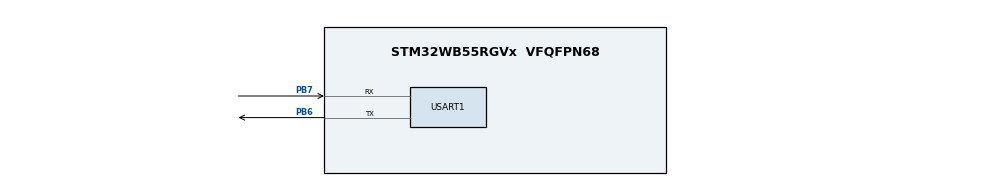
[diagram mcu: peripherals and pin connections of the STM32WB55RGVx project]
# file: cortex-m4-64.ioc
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Mcu.Family=STM32WB
PB7.GPIO_PuPd=GPIO_PULLUP
VP_STMicroelectronics.X-CUBE-AI_VS_ArtificialOoIntelligenceJjXAaCUBEAaAI_6.0.0.Mode=ArtificialOoIntelligenceJjXAaCUBEAaAI
STMicroelectronics.X-CUBE-AI.6.0.0.ModelActualCompression-013ac4f5febfa73d31e41960009db4c5f31622ea593a83edd321e333f884b972=6.71
RCC.CortexFreq_Value=64000000
STMicroelectronics.X-CUBE-AI.6.0.0.MaximumSizeOfInputLayer=AI_NETWORK_IN_1_SIZE_BYTES
STMicroelectronics.X-CUBE-AI.6.0.0.ModelStructureFile-013ac4f5febfa73d31e41960009db4c5f31622ea593a83edd321e333f884b972=/Users/dominikpiorkowski/Desktop/drive/projekty/ML models/fashion_mnist/fashion_mnist.h5
STMicroelectronics.X-CUBE-AI.6.0.0.ModelType-013ac4f5febfa73d31e41960009db4c5f31622ea593a83edd321e333f884b972=Saved model
PB6.GPIO_PuPd=GPIO_PULLUP
STMicroelectronics.X-CUBE-AI.6.0.0.MaximumSizeOfOutputLayer=AI_NETWORK_OUT_1_SIZE_BYTES
STMicroelectronics.X-CUBE-AI.6.0.0.ModelFlashOccupation-013ac4f5febfa73d31e41960009db4c5f31622ea593a83edd321e333f884b972=246248
VP_TIM16_VS_ClockSourceINT.Mode=Enable_Timer
STMicroelectronics.X-CUBE-AI.6.0.0.StackSize=0x1000
RCC.AHB2CLKDivider=RCC_SYSCLK_DIV2
RCC.SYSCLKSource=RCC_SYSCLKSOURCE_PLLCLK
ProjectManager.StackSize=0x1000
STMicroelectronics.X-CUBE-AI.6.0.0.ModelName-013ac4f5febfa73d31e41960009db4c5f31622ea593a83edd321e333f884b972=network
USART1.VirtualMode-Asynchronous=VM_ASYNC
PA13.Signal=SYS_JTMS-SWDIO
STMicroelectronics.X-CUBE-AI.6.0.0.ModelHashList=013ac4f5febfa73d31e41960009db4c5f31622ea593a83edd321e333f884b972
ProjectManager.TargetToolchain=STM32CubeIDE
STMicroelectronics.X-CUBE-AI.6.0.0.InternalRamActivationBufferMaxSize=AI_NETWORK_DATA_ACTIVATIONS_SIZE
RCC.HCLKFreq_Value=64000000
RCC.APB2TimFreq_Value=64000000
PB6.Signal=USART1_TX
PB6.Mode=Asynchronous
STMicroelectronics.X-CUBE-AI.6.0.0.WorkingBufferStartAddrList=0xFFFFFFFF
STMicroelectronics.X-CUBE-AI.6.0.0.ModelNameList=network
STMicroelectronics.X-CUBE-AI.6.0.0.MaximumNumberOfOutputLayer=1
RCC.LSE_VALUE=32768
STMicroelectronics.X-CUBE-AI.6.0.0.ModelRamOccupation-013ac4f5febfa73d31e41960009db4c5f31622ea593a83edd321e333f884b972=67688
RCC.AHBFreq_Value=64000000
RCC.HSE_VALUE=8000000
PB3.Mode=Trace_Asynchronous_SW
board=custom
RCC.VCOOutputFreq_Value=128000000
RCC.Cortex2_Div=SYSTICK_CLKSOURCE_HCLK_DIV8
TIM16.Period=10000-1
RCC.APB2Freq_Value=64000000
STMicroelectronics.X-CUBE-AI.6.0.0.ModelCompression-013ac4f5febfa73d31e41960009db4c5f31622ea593a83edd321e333f884b972=8
PA14.Mode=Trace_Asynchronous_SW
STMicroelectronics.X-CUBE-AI.6.0.0.XAaCUBEAaAICcArtificialOoIntelligenceJjCore=true
PB7.Signal=USART1_RX
PA13.Mode=Trace_Asynchronous_SW
Mcu.Name=STM32WB55RGVx
STMicroelectronics.X-CUBE-AI.6.0.0.ModelKind-013ac4f5febfa73d31e41960009db4c5f31622ea593a83edd321e333f884b972=KERAS
RCC.APB3Freq_Value=16000000
PB3.Signal=SYS_JTDO-SWO
RCC.SYSCLKFreq_VALUE=64000000
Mcu.Package=VFQFPN68
PB7.Mode=Asynchronous
PA14.Signal=SYS_JTCK-SWCLK
STMicroelectronics.X-CUBE-AI.6.0.0.MaximumNumberOfInputLayer=1
ProjectManager.HeapSize=0x200
STMicroelectronics.X-CUBE-AI.6.0.0.HeapSize=0x200
RCC.HSI_VALUE=16000000
NVIC.TIM1_UP_TIM16_IRQn=true\:0\:0\:false\:false\:true\:true\:true
NVIC.PriorityGroup=NVIC_PRIORITYGROUP_4
STMicroelectronics.X-CUBE-AI.6.0.0.ModelMacc-013ac4f5febfa73d31e41960009db4c5f31622ea593a83edd321e333f884b972=2323968
RCC.PLLN=32
TIM16.AutoReloadPreload=TIM_AUTORELOAD_PRELOAD_ENABLE
RCC.APB1TimFreq_Value=64000000
TIM16.Prescaler=6400-1
STMicroelectronics.X-CUBE-AI.6.0.0.LatestDirectoryUsed-013ac4f5febfa73d31e41960009db4c5f31622ea593a83edd321e333f884b972=/Users/dominikpiorkowski/Desktop/drive/projekty/ML models/fashion_mnist
RCC.APB1Freq_Value=64000000
VP_CRC_VS_CRC.Mode=CRC_Activate
STMicroelectronics.X-CUBE-AI.6.0.0.ActivationBufferSizeList=67688
RCC.HSI48_VALUE=48000000

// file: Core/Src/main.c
/* USER CODE BEGIN Header */
/**
  ******************************************************************************
  * @file           : main.c
  * @brief          : Main program body
  ******************************************************************************
  * @attention
  *
  * Copyright (c)	2021 STMicroelectronics,
  * 				2021 Dominik Piórkowski.
  *
  * All rights reserved.
  *
  * This software component is licensed by ST under BSD 3-Clause license,
  * the "License"; You may not use this file except in compliance with the
  * License. You may obtain a copy of the License at:
  *                        opensource.org/licenses/BSD-3-Clause
  *
  ******************************************************************************
  */
/* USER CODE END Header */
#include "main.h"
#include "crc.h"
#include "tim.h"
#include "usart.h"
#include "gpio.h"

/* USER CODE BEGIN Includes */
#include <stdio.h>

#include "ai_platform.h"
#include "network.h"
#include "network_data.h"
#include "test_input.h"
/* USER CODE END Includes */

/* USER CODE BEGIN PV */
char buf[50];
int buf_len = 0;
ai_handle network;

uint32_t timer_counter = 0;
uint32_t timestamp = 0;

float aiOutData[3][AI_NETWORK_OUT_1_SIZE];
uint8_t activations[AI_NETWORK_DATA_ACTIVATIONS_SIZE];
const char* labels[AI_NETWORK_OUT_1_SIZE] = {
		"top", "trouser", "pullover", "dress", "coat", "sandal", "shirt", "sneaker", "bag", "ankle boot"
};
/* USER CODE END PV */

void SystemClock_Config(void);
/* USER CODE BEGIN PFP */
static void AI_Init(ai_handle w_addr, ai_handle act_addr);
static void AI_Run(float *pIn, float *pOut);
static uint32_t argmax(const float * values, uint32_t len);
/* USER CODE END PFP */

int main(void)
{
  /* USER CODE BEGIN 1 */
	//  normalise data to range [0,1]
	for(int i = 0; i < AI_NETWORK_IN_1_SIZE; i++)
	{
		aiInDataShirt[i] = aiInDataShirt[i] / 255.0;
	}
  /* USER CODE END 1 */

  /* MCU Configuration--------------------------------------------------------*/

  /* Reset of all peripherals, Initializes the Flash interface and the Systick. */
  HAL_Init();

  /* Configure the system clock */
  SystemClock_Config();

  /* Initialize all configured peripherals */
  MX_GPIO_Init();
  MX_TIM16_Init();
  MX_CRC_Init();
  MX_USART1_UART_Init();

  /* USER CODE BEGIN 2 */
  AI_Init(ai_network_data_weights_get(), activations);

  //  Start timer/counter
  HAL_TIM_Base_Start_IT(&htim16);
  /* USER CODE END 2 */

  /* Infinite loop */
  /* USER CODE BEGIN WHILE */
  while (1)
  {
	  buf_len = sprintf(buf, "M4-64 Running IC inference \n");
	  HAL_UART_Transmit(&huart1, (uint8_t *)buf, buf_len, 100);

	  timestamp = htim16.Instance->CNT;

	  //	  shirt
	  AI_Run(aiInDataShirt, aiOutData[0]);

	  //	  pullover
	  AI_Run(aiInDataPullover, aiOutData[1]);

	  //	  trouser
	  AI_Run(aiInDataTrouser, aiOutData[2]);

	  uint32_t predicted_class_1 = argmax(aiOutData[0], AI_NETWORK_OUT_1_SIZE);
	  uint32_t predicted_class_2 = argmax(aiOutData[1], AI_NETWORK_OUT_1_SIZE);
	  uint32_t predicted_class_3 = argmax(aiOutData[2], AI_NETWORK_OUT_1_SIZE);

	  buf_len = sprintf(buf, "Inference duration: (%lu 10s) + %lu*1ms \n", timer_counter, (htim16.Instance->CNT - timestamp));
	  HAL_UART_Transmit(&huart1, (uint8_t *)buf, buf_len, 100);

	  buf_len = sprintf(buf, "1 predicted class: %d - %s \n", (int) predicted_class_1, labels[predicted_class_1]);
	  HAL_UART_Transmit(&huart1, (uint8_t *)buf, buf_len, 100);
	  buf_len = sprintf(buf, "2 predicted class: %d - %s \n", (int) predicted_class_2, labels[predicted_class_2]);
	  HAL_UART_Transmit(&huart1, (uint8_t *)buf, buf_len, 100);
	  buf_len = sprintf(buf, "3 predicted class: %d - %s \n", (int) predicted_class_3, labels[predicted_class_3]);
	  HAL_UART_Transmit(&huart1, (uint8_t *)buf, buf_len, 100);
    /* USER CODE END WHILE */

  }
}

void SystemClock_Config(void)
{
  RCC_OscInitTypeDef RCC_OscInitStruct = {0};
  RCC_ClkInitTypeDef RCC_ClkInitStruct = {0};
  RCC_PeriphCLKInitTypeDef PeriphClkInitStruct = {0};

  /** Configure the main internal regulator output voltage
  */
  __HAL_PWR_VOLTAGESCALING_CONFIG(PWR_REGULATOR_VOLTAGE_SCALE1);
  /** Initializes the RCC Oscillators according to the specified parameters
  * in the RCC_OscInitTypeDef structure.
  */
  RCC_OscInitStruct.OscillatorType = RCC_OSCILLATORTYPE_HSI|RCC_OSCILLATORTYPE_MSI;
  RCC_OscInitStruct.HSIState = RCC_HSI_ON;
  RCC_OscInitStruct.MSIState = RCC_MSI_ON;
  RCC_OscInitStruct.HSICalibrationValue = RCC_HSICALIBRATION_DEFAULT;
  RCC_OscInitStruct.MSICalibrationValue = RCC_MSICALIBRATION_DEFAULT;
  RCC_OscInitStruct.MSIClockRange = RCC_MSIRANGE_6;
  RCC_OscInitStruct.PLL.PLLState = RCC_PLL_ON;
  RCC_OscInitStruct.PLL.PLLSource = RCC_PLLSOURCE_MSI;
  RCC_OscInitStruct.PLL.PLLM = RCC_PLLM_DIV1;
  RCC_OscInitStruct.PLL.PLLN = 32;
  RCC_OscInitStruct.PLL.PLLP = RCC_PLLP_DIV2;
  RCC_OscInitStruct.PLL.PLLR = RCC_PLLR_DIV2;
  RCC_OscInitStruct.PLL.PLLQ = RCC_PLLQ_DIV2;
  if (HAL_RCC_OscConfig(&RCC_OscInitStruct) != HAL_OK)
  {
    Error_Handler();
  }
  /** Configure the SYSCLKSource, HCLK, PCLK1 and PCLK2 clocks dividers
  */
  RCC_ClkInitStruct.ClockType = RCC_CLOCKTYPE_HCLK4|RCC_CLOCKTYPE_HCLK2
                              |RCC_CLOCKTYPE_HCLK|RCC_CLOCKTYPE_SYSCLK
                              |RCC_CLOCKTYPE_PCLK1|RCC_CLOCKTYPE_PCLK2;
  RCC_ClkInitStruct.SYSCLKSource = RCC_SYSCLKSOURCE_PLLCLK;
  RCC_ClkInitStruct.AHBCLKDivider = RCC_SYSCLK_DIV1;
  RCC_ClkInitStruct.APB1CLKDivider = RCC_HCLK_DIV1;
  RCC_ClkInitStruct.APB2CLKDivider = RCC_HCLK_DIV1;
  RCC_ClkInitStruct.AHBCLK2Divider = RCC_SYSCLK_DIV2;
  RCC_ClkInitStruct.AHBCLK4Divider = RCC_SYSCLK_DIV1;

  if (HAL_RCC_ClockConfig(&RCC_ClkInitStruct, FLASH_LATENCY_3) != HAL_OK)
  {
    Error_Handler();
  }
  /** Initializes the peripherals clocks
  */
  PeriphClkInitStruct.PeriphClockSelection = RCC_PERIPHCLK_SMPS|RCC_PERIPHCLK_USART1;
  PeriphClkInitStruct.Usart1ClockSelection = RCC_USART1CLKSOURCE_PCLK2;
  PeriphClkInitStruct.SmpsClockSelection = RCC_SMPSCLKSOURCE_HSI;
  PeriphClkInitStruct.SmpsDivSelection = RCC_SMPSCLKDIV_RANGE1;
  if (HAL_RCCEx_PeriphCLKConfig(&PeriphClkInitStruct) != HAL_OK)
  {
    Error_Handler();
  }
}

/* USER CODE BEGIN 4 */
void HAL_TIM_PeriodElapsedCallback(TIM_HandleTypeDef *htim)
{
	if (htim == &htim16 )
	{
		++timer_counter;
	}
}

static void AI_Init(ai_handle w_addr, ai_handle act_addr)
{
	ai_error err;

	/* 1 - Create an instance of the model */
	err = ai_network_create(&network, AI_NETWORK_DATA_CONFIG);
	if (err.type != AI_ERROR_NONE) {
		printf("ai_network_create error - type=%d code=%d\r\n", err.type, err.code);
		Error_Handler();
	}

	/* 2 - Initialize the instance */
	const ai_network_params params = {
			AI_NETWORK_DATA_WEIGHTS(w_addr),
			AI_NETWORK_DATA_ACTIVATIONS(act_addr)
	};

	if (!ai_network_init(network, &params))
	{
		err = ai_network_get_error(network);
		printf("ai_network_init error - type=%d code=%d\r\n", err.type, err.code);
		Error_Handler();
	}
}
static void AI_Run(float *pIn, float *pOut)
{
	ai_i32 batch;
	ai_error err;

	/* 1 - Create the AI buffer IO handlers with the default definition */
	ai_buffer ai_input[AI_NETWORK_IN_NUM] = AI_NETWORK_IN;
	ai_buffer ai_output[AI_NETWORK_OUT_NUM] = AI_NETWORK_OUT;

	/* 2 - Update IO handlers with the data payload */
	ai_input[0].n_batches = 1;
	ai_input[0].data = AI_HANDLE_PTR(pIn);
	ai_output[0].n_batches = 1;
	ai_output[0].data = AI_HANDLE_PTR(pOut);

	batch = ai_network_run(network, ai_input, ai_output);
	if (batch != 1)
	{
		err = ai_network_get_error(network);
		buf_len = sprintf(buf, "AI ai_network_run error - type=%d code=%d \n", err.type, err.code);
		HAL_UART_Transmit(&huart1, (uint8_t *)buf, buf_len, 100);
		Error_Handler();
	}
}
static uint32_t argmax(const float * values, uint32_t len)
{
	float max_value = values[0];
	uint32_t max_index = 0;
	for (uint32_t i = 1; i < len; i++)
	{
		if (values[i] > max_value)
		{
			max_value = values[i];
			max_index = i;
		}
	}
	return max_index;
}
/* USER CODE END 4 */

void Error_Handler(void)
{
  __disable_irq();
  while (1)
  {
  }
}

/************************ (C) COPYRIGHT STMicroelectronics *****END OF FILE****/
